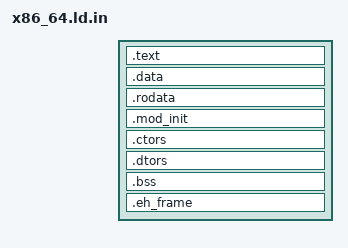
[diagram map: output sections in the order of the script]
ENTRY(loader)
TARGET(elf64-x86-64)

SECTIONS
{
	. = ${MOMENTUM_KERNEL_BASE_VADDR};
	kernel_start = .;
	.text ALIGN (0x1000) : AT(ADDR(.text) - ${MOMENTUM_KERNEL_BASE_VADDR} + ${MOMENTUM_KERNEL_BASE_PADDR})
	{
		*(.text*)
		. = ALIGN(4096);
	}
	
	.data ALIGN (0x1000) : AT(ADDR(.data) - ${MOMENTUM_KERNEL_BASE_VADDR} + ${MOMENTUM_KERNEL_BASE_PADDR})
	{
		*(.data)
        . = ALIGN(4096);
	}

	.rodata ALIGN (0x1000) : AT(ADDR(.rodata) - ${MOMENTUM_KERNEL_BASE_VADDR} + ${MOMENTUM_KERNEL_BASE_PADDR})
	{
		*(.rodata*)
        . = ALIGN(4096);
	}
	
	__MOD_LIST__ = .;
    .mod_init ALIGN (0x1000) : AT(ADDR(.mod_init) - ${MOMENTUM_KERNEL_BASE_VADDR} + ${MOMENTUM_KERNEL_BASE_PADDR})
	{
		*(.mod_init)
	}
	__MOD_END__ = .;
    
	.ctors ALIGN (0x1000) : AT(ADDR(.ctors) - ${MOMENTUM_KERNEL_BASE_VADDR} + ${MOMENTUM_KERNEL_BASE_PADDR})
	{
		__CTOR_LIST__ = .;
		*(.ctors)
		*(.init_array)
	}
	__CTOR_END__ = .;
    
	.dtors ALIGN (0x1000) : AT(ADDR(.dtors) - ${MOMENTUM_KERNEL_BASE_VADDR} + ${MOMENTUM_KERNEL_BASE_PADDR})
	{
		*(.dtors)
		*(.fini_array)
	}
	
	.bss ALIGN (0x1000) : AT(ADDR(.bss) - ${MOMENTUM_KERNEL_BASE_VADDR} + ${MOMENTUM_KERNEL_BASE_PADDR})
	{
		_sbss = .;
		*(COMMON)
		*(.bss)
		_ebss = .;
		. = ALIGN(4096);
	}
	
	.eh_frame ALIGN (0x1000) : AT(ADDR(.eh_frame) - ${MOMENTUM_KERNEL_BASE_VADDR} + ${MOMENTUM_KERNEL_BASE_PADDR})
	{
		*(.eh_frame)
		. = ALIGN(4096);
	}
	kernel_end = .;
}
